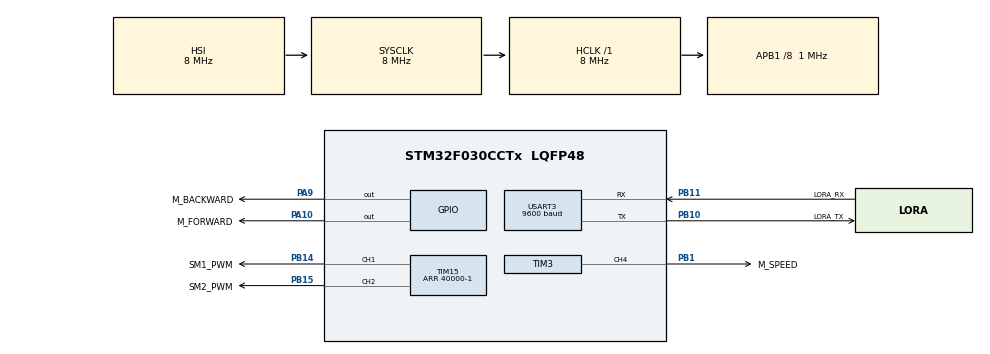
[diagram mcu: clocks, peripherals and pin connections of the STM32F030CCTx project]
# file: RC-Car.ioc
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Mcu.Family=STM32F0
Mcu.Name=STM32F030CCTx
Mcu.Package=LQFP48
NVIC.USART3_6_IRQn=true\:0\:0\:false\:false\:true\:true\:true\:true
PA10.GPIO_Label=M_FORWARD
PA10.GPIO_PuPd=GPIO_PULLDOWN
PA10.Signal=GPIO_Output
PA13.Mode=Serial_Wire
PA13.Signal=SYS_SWDIO
PA14.Mode=Serial_Wire
PA14.Signal=SYS_SWCLK
PA9.GPIO_Label=M_BACKWARD
PA9.GPIO_PuPd=GPIO_PULLDOWN
PA9.Signal=GPIO_Output
PB1.GPIO_Label=M_SPEED
PB1.GPIO_PuPd=GPIO_PULLDOWN
PB1.Signal=S_TIM3_CH4
PB10.GPIO_Label=LORA_TX
PB10.Mode=Asynchronous
PB10.Signal=USART3_TX
PB11.GPIO_Label=LORA_RX
PB11.Mode=Asynchronous
PB11.Signal=USART3_RX
PB14.GPIO_Label=SM1_PWM
PB14.Signal=S_TIM15_CH1
PB15.GPIO_Label=SM2_PWM
PB15.Signal=S_TIM15_CH2
PF0-OSC_IN.Signal=RCC_OSC_IN
PF1-OSC_OUT.Signal=RCC_OSC_OUT
ProjectManager.HeapSize=0x200
ProjectManager.StackSize=0x400
ProjectManager.TargetToolchain=STM32CubeIDE
RCC.AHBFreq_Value=8000000
RCC.APB1CLKDivider=RCC_HCLK_DIV8
RCC.APB1Freq_Value=1000000
RCC.APB1TimFreq_Value=2000000
RCC.HCLKFreq_Value=8000000
RCC.SYSCLKFreq_VALUE=8000000
SH.S_TIM15_CH1.0=TIM15_CH1,PWM Generation1 CH1
SH.S_TIM15_CH2.0=TIM15_CH2,PWM Generation2 CH2
SH.S_TIM3_CH4.0=TIM3_CH4,PWM Generation4 CH4
TIM15.AutoReloadPreload=TIM_AUTORELOAD_PRELOAD_ENABLE
TIM15.Channel-PWM\ Generation1\ CH1=TIM_CHANNEL_1
TIM15.Channel-PWM\ Generation2\ CH2=TIM_CHANNEL_2
TIM15.Period=40000-1
TIM3.Channel-PWM\ Generation4\ CH4=TIM_CHANNEL_4
TIM3.Period=100-1
TIM3.Pulse-PWM\ Generation4\ CH4=50-1
USART3.BaudRate=9600
USART3.VirtualMode-Asynchronous=VM_ASYNC
VP_TIM15_VS_ClockSourceINT.Mode=Internal
VP_TIM3_VS_ClockSourceINT.Mode=Internal
board=custom

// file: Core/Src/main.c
/* USER CODE BEGIN Header */
/**
  ******************************************************************************
  * @file           : main.c
  * @brief          : Main program body
  ******************************************************************************
  * @attention
  *
  * Copyright (c) 2024 STMicroelectronics.
  * All rights reserved.
  *
  * This software is licensed under terms that can be found in the LICENSE file
  * in the root directory of this software component.
  * If no LICENSE file comes with this software, it is provided AS-IS.
  *
  ******************************************************************************
  */
/* USER CODE END Header */
#include "main.h"

/* USER CODE BEGIN Includes */

#include "rc_car.h"

/* USER CODE END Includes */

TIM_HandleTypeDef htim3;
TIM_HandleTypeDef htim15;

UART_HandleTypeDef huart3;

void SystemClock_Config(void);
static void MX_GPIO_Init(void);
static void MX_TIM15_Init(void);
static void MX_USART3_UART_Init(void);
static void MX_TIM3_Init(void);

int main(void)
{

  /* MCU Configuration--------------------------------------------------------*/

  /* Reset of all peripherals, Initializes the Flash interface and the Systick. */
  HAL_Init();

  /* Configure the system clock */
  SystemClock_Config();

  /* Initialize all configured peripherals */
  MX_GPIO_Init();
  MX_TIM15_Init();
  MX_USART3_UART_Init();
  MX_TIM3_Init();
  /* USER CODE BEGIN 2 */

  rc_car_init();

  /* USER CODE END 2 */

  /* Infinite loop */
  while (1)
  {

	  rc_car_process();

  }
}

void SystemClock_Config(void)
{
  RCC_OscInitTypeDef RCC_OscInitStruct = {0};
  RCC_ClkInitTypeDef RCC_ClkInitStruct = {0};

  /** Initializes the RCC Oscillators according to the specified parameters
  * in the RCC_OscInitTypeDef structure.
  */
  RCC_OscInitStruct.OscillatorType = RCC_OSCILLATORTYPE_HSI;
  RCC_OscInitStruct.HSIState = RCC_HSI_ON;
  RCC_OscInitStruct.HSICalibrationValue = RCC_HSICALIBRATION_DEFAULT;
  RCC_OscInitStruct.PLL.PLLState = RCC_PLL_NONE;
  if (HAL_RCC_OscConfig(&RCC_OscInitStruct) != HAL_OK)
  {
    Error_Handler();
  }

  /** Initializes the CPU, AHB and APB buses clocks
  */
  RCC_ClkInitStruct.ClockType = RCC_CLOCKTYPE_HCLK|RCC_CLOCKTYPE_SYSCLK
                              |RCC_CLOCKTYPE_PCLK1;
  RCC_ClkInitStruct.SYSCLKSource = RCC_SYSCLKSOURCE_HSI;
  RCC_ClkInitStruct.AHBCLKDivider = RCC_SYSCLK_DIV1;
  RCC_ClkInitStruct.APB1CLKDivider = RCC_HCLK_DIV8;

  if (HAL_RCC_ClockConfig(&RCC_ClkInitStruct, FLASH_LATENCY_0) != HAL_OK)
  {
    Error_Handler();
  }
}

static void MX_TIM3_Init(void)
{

  TIM_ClockConfigTypeDef sClockSourceConfig = {0};
  TIM_MasterConfigTypeDef sMasterConfig = {0};
  TIM_OC_InitTypeDef sConfigOC = {0};

  htim3.Instance = TIM3;
  htim3.Init.Prescaler = 0;
  htim3.Init.CounterMode = TIM_COUNTERMODE_UP;
  htim3.Init.Period = 100-1;
  htim3.Init.ClockDivision = TIM_CLOCKDIVISION_DIV1;
  htim3.Init.AutoReloadPreload = TIM_AUTORELOAD_PRELOAD_DISABLE;
  if (HAL_TIM_Base_Init(&htim3) != HAL_OK)
  {
    Error_Handler();
  }
  sClockSourceConfig.ClockSource = TIM_CLOCKSOURCE_INTERNAL;
  if (HAL_TIM_ConfigClockSource(&htim3, &sClockSourceConfig) != HAL_OK)
  {
    Error_Handler();
  }
  if (HAL_TIM_PWM_Init(&htim3) != HAL_OK)
  {
    Error_Handler();
  }
  sMasterConfig.MasterOutputTrigger = TIM_TRGO_RESET;
  sMasterConfig.MasterSlaveMode = TIM_MASTERSLAVEMODE_DISABLE;
  if (HAL_TIMEx_MasterConfigSynchronization(&htim3, &sMasterConfig) != HAL_OK)
  {
    Error_Handler();
  }
  sConfigOC.OCMode = TIM_OCMODE_PWM1;
  sConfigOC.Pulse = 50-1;
  sConfigOC.OCPolarity = TIM_OCPOLARITY_HIGH;
  sConfigOC.OCFastMode = TIM_OCFAST_DISABLE;
  if (HAL_TIM_PWM_ConfigChannel(&htim3, &sConfigOC, TIM_CHANNEL_4) != HAL_OK)
  {
    Error_Handler();
  }
  HAL_TIM_MspPostInit(&htim3);

}

static void MX_TIM15_Init(void)
{

  TIM_ClockConfigTypeDef sClockSourceConfig = {0};
  TIM_MasterConfigTypeDef sMasterConfig = {0};
  TIM_OC_InitTypeDef sConfigOC = {0};
  TIM_BreakDeadTimeConfigTypeDef sBreakDeadTimeConfig = {0};

  htim15.Instance = TIM15;
  htim15.Init.Prescaler = 0;
  htim15.Init.CounterMode = TIM_COUNTERMODE_UP;
  htim15.Init.Period = 40000-1;
  htim15.Init.ClockDivision = TIM_CLOCKDIVISION_DIV1;
  htim15.Init.RepetitionCounter = 0;
  htim15.Init.AutoReloadPreload = TIM_AUTORELOAD_PRELOAD_ENABLE;
  if (HAL_TIM_Base_Init(&htim15) != HAL_OK)
  {
    Error_Handler();
  }
  sClockSourceConfig.ClockSource = TIM_CLOCKSOURCE_INTERNAL;
  if (HAL_TIM_ConfigClockSource(&htim15, &sClockSourceConfig) != HAL_OK)
  {
    Error_Handler();
  }
  if (HAL_TIM_PWM_Init(&htim15) != HAL_OK)
  {
    Error_Handler();
  }
  sMasterConfig.MasterOutputTrigger = TIM_TRGO_RESET;
  sMasterConfig.MasterSlaveMode = TIM_MASTERSLAVEMODE_DISABLE;
  if (HAL_TIMEx_MasterConfigSynchronization(&htim15, &sMasterConfig) != HAL_OK)
  {
    Error_Handler();
  }
  sConfigOC.OCMode = TIM_OCMODE_PWM1;
  sConfigOC.Pulse = 0;
  sConfigOC.OCPolarity = TIM_OCPOLARITY_HIGH;
  sConfigOC.OCNPolarity = TIM_OCNPOLARITY_HIGH;
  sConfigOC.OCFastMode = TIM_OCFAST_DISABLE;
  sConfigOC.OCIdleState = TIM_OCIDLESTATE_RESET;
  sConfigOC.OCNIdleState = TIM_OCNIDLESTATE_RESET;
  if (HAL_TIM_PWM_ConfigChannel(&htim15, &sConfigOC, TIM_CHANNEL_1) != HAL_OK)
  {
    Error_Handler();
  }
  if (HAL_TIM_PWM_ConfigChannel(&htim15, &sConfigOC, TIM_CHANNEL_2) != HAL_OK)
  {
    Error_Handler();
  }
  sBreakDeadTimeConfig.OffStateRunMode = TIM_OSSR_DISABLE;
  sBreakDeadTimeConfig.OffStateIDLEMode = TIM_OSSI_DISABLE;
  sBreakDeadTimeConfig.LockLevel = TIM_LOCKLEVEL_OFF;
  sBreakDeadTimeConfig.DeadTime = 0;
  sBreakDeadTimeConfig.BreakState = TIM_BREAK_DISABLE;
  sBreakDeadTimeConfig.BreakPolarity = TIM_BREAKPOLARITY_HIGH;
  sBreakDeadTimeConfig.AutomaticOutput = TIM_AUTOMATICOUTPUT_DISABLE;
  if (HAL_TIMEx_ConfigBreakDeadTime(&htim15, &sBreakDeadTimeConfig) != HAL_OK)
  {
    Error_Handler();
  }
  HAL_TIM_MspPostInit(&htim15);

}

static void MX_USART3_UART_Init(void)
{

  huart3.Instance = USART3;
  huart3.Init.BaudRate = 9600;
  huart3.Init.WordLength = UART_WORDLENGTH_8B;
  huart3.Init.StopBits = UART_STOPBITS_1;
  huart3.Init.Parity = UART_PARITY_NONE;
  huart3.Init.Mode = UART_MODE_TX_RX;
  huart3.Init.HwFlowCtl = UART_HWCONTROL_NONE;
  huart3.Init.OverSampling = UART_OVERSAMPLING_16;
  huart3.Init.OneBitSampling = UART_ONE_BIT_SAMPLE_DISABLE;
  huart3.AdvancedInit.AdvFeatureInit = UART_ADVFEATURE_NO_INIT;
  if (HAL_UART_Init(&huart3) != HAL_OK)
  {
    Error_Handler();
  }

}

static void MX_GPIO_Init(void)
{
  GPIO_InitTypeDef GPIO_InitStruct = {0};

  /* GPIO Ports Clock Enable */
  __HAL_RCC_GPIOF_CLK_ENABLE();
  __HAL_RCC_GPIOB_CLK_ENABLE();
  __HAL_RCC_GPIOA_CLK_ENABLE();

  /*Configure GPIO pin Output Level */
  HAL_GPIO_WritePin(GPIOA, M_BACKWARD_Pin|M_FORWARD_Pin, GPIO_PIN_RESET);

  /*Configure GPIO pins : M_BACKWARD_Pin M_FORWARD_Pin */
  GPIO_InitStruct.Pin = M_BACKWARD_Pin|M_FORWARD_Pin;
  GPIO_InitStruct.Mode = GPIO_MODE_OUTPUT_PP;
  GPIO_InitStruct.Pull = GPIO_PULLDOWN;
  GPIO_InitStruct.Speed = GPIO_SPEED_FREQ_LOW;
  HAL_GPIO_Init(GPIOA, &GPIO_InitStruct);

}

void Error_Handler(void)
{
  __disable_irq();
  while (1)
  {
  }
}
